# ATSAM4CMP32C_1 register map
Vendor: Atmel; Series: SAM4CM; File version: 0
CPU: CM4 r0p0, selectable endian, no MPU, FPU, 4 interrupt priority bits
Registers are 32-bit, read-write, reset 0x0 unless marked. A register's access mark holds for its fields unless they carry their own. Offsets are from the block's base; [hi:lo] are bit positions; {n}, {i} and the like mark numbered series; 'fields as' and 'values as' point back to an identical list.

## SLCDC — Segment LCD Controller
Base 0x4003C000; register names take the prefix SLCDC_
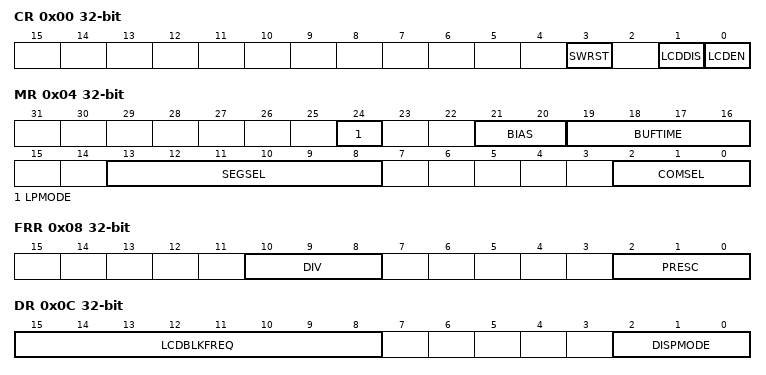
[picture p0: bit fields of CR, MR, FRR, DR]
0x00 CR wo reset not defined — SLCDC Control Register
  [3] SWRST — Software Reset
  [1] LCDDIS — Disable LCDC
  [0] LCDEN — Enable the LCDC
0x04 MR — SLCDC Mode Register
  [24] LPMODE — Low Power Mode (Taken into account from the next begin of frame.)
  [21:20] BIAS — LCD Display Configuration
    0=STATIC; 1=BIAS_1_2; 2=BIAS_1_3
  [19:16] BUFTIME — Buffer On-Time
    0=OFF (Nominal drive time is 0% of SCLK period); 1=X2_SCLK_PERIOD (Nominal drive time is 2 periods of SCLK clock); 2=X4_SCLK_PERIOD (Nominal drive time is 4 periods of SCLK clock); 3=X8_SCLK_PERIOD (Nominal drive time is 8 periods of SCLK clock); 4=X16_SCLK_PERIOD (Nominal drive time is 16 periods of SCLK clock); 5=X32_SCLK_PERIOD (Nominal drive time is 32 periods of SCLK clock); 6=X64_SCLK_PERIOD (Nominal drive time is 64 periods of SCLK clock); 7=X128_SCLK_PERIOD (Nominal drive time is 128 periods of SCLK clock); 8=PERCENT_50 (Nominal drive time is 50% of SCLK period); 9=PERCENT_100 (Nominal drive time is 100% of SCLK period)
  [13:8] SEGSEL — Selection of the Number of Segments
  [2:0] COMSEL — Selection of the Number of Commons
    0=COM_0 (COM0 is driven by SLCDC, COM1:5 are driven by digital function); 1=COM_0TO1 (COM0:1 are driven by SLCDC, COM2:5 are driven by digital function); 2=COM_0TO2 (COM0:2 are driven by SLCDC, COM3:5 are driven by digital function); 3=COM_0TO3 (COM0:3 are driven by SLCDC, COM4:5 are driven by digital function); 4=COM_0TO4 (COM0:4 are driven by SLCDC, COM5 is driven by digital function); 5=COM_0TO5 (COM0:5 are driven by SLCDC, No COM pin driven by digital function)
0x08 FRR — SLCDC Frame Rate Register
  [10:8] DIV — Clock Division
    {v}=PRESC_CLK_DIV{v+1} (clock output from prescaler is divided by {v+1}) (v=0..7)
  [2:0] PRESC — Clock Prescaler
    0=SCLK_DIV8 (slow clock is divided by 8); 1=SCLK_DIV16 (slow clock is divided by 16); 2=SCLK_DIV32 (slow clock is divided by 32); 3=SCLK_DIV64 (slow clock is divided by 64); 4=SCLK_DIV128 (slow clock is divided by 128); 5=SCLK_DIV256 (slow clock is divided by 256); 6=SCLK_DIV512 (slow clock is divided by 512); 7=SCLK_DIV1024 (slow clock is divided by 1024)
0x0C DR — SLCDC Display Register
  [15:8] LCDBLKFREQ — LCD Blinking Frequency Selection
  [2:0] DISPMODE — Display Mode Register
    0=NORMAL (Normal Mode: Latched data are displayed.); 1=FORCE_OFF (Force Off Mode: All pixels are invisible. (The SLCDC memory is unchanged.)); 2=FORCE_ON (Force On Mode All pixels are visible. (The SLCDC memory is unchanged.)); 3=BLINKING (Blinking Mode: All pixels are alternately turned off to the predefined state in SLCDC memory at LCDBLKFREQ frequency. (The SLCDC memory is unchanged.)); 4=INVERTED (Inverted Mode: All pixels are set in the inverted state as defined in SLCDC memory. (The SLCDC memory is unchanged.)); 5=INVERTED_BLINK (Inverted Blinking Mode: All pixels are alternately turned off to the predefined opposite state in SLCDC memory at LCDBLKFREQ frequency. (The SLCDC memory is unchanged.)); 6=USER_BUFFER_LOAD (User Buffer Only Load Mode: Blocks the automatic transfer from User Buffer to Display Buffer.); 7=BUFFERS_SWAP (Buffer Swap Mode: All pixels are alternatively assigned to the state defined in the User Buffer, then to the state defined in the Display Buffer at LCDBLKFREQ frequency.)
0x10 SR ro — SLCDC Status Register
  [0] ENA — Enable Status (Automatically Set/Reset)
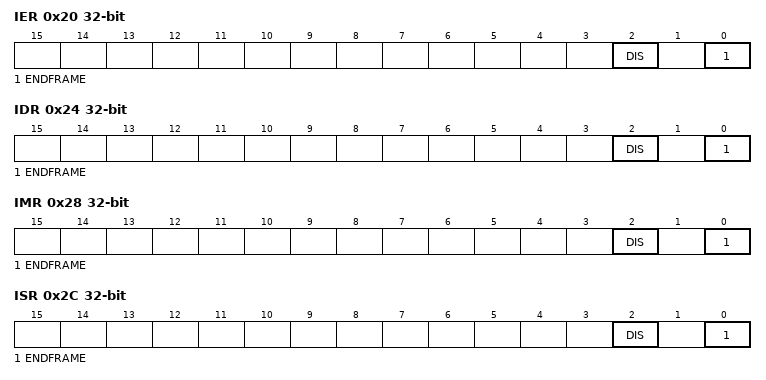
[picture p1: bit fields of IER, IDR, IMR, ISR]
0x20 IER wo reset not defined — SLCDC Interrupt Enable Register
  [2] DIS — Disable Interrupt Enable
  [0] ENDFRAME — End of Frame Interrupt Enable
0x24 IDR wo reset not defined — SLCDC Interrupt Disable Register
  [2] DIS — Disable Interrupt Disable
  [0] ENDFRAME — End of Frame Interrupt Disable
0x28 IMR wo reset not defined — SLCDC Interrupt Mask Register
  [2] DIS — Disable Interrupt Mask
  [0] ENDFRAME — End of Frame Interrupt Mask
0x2C ISR ro — SLCDC Interrupt Status Register
  fields as IMR
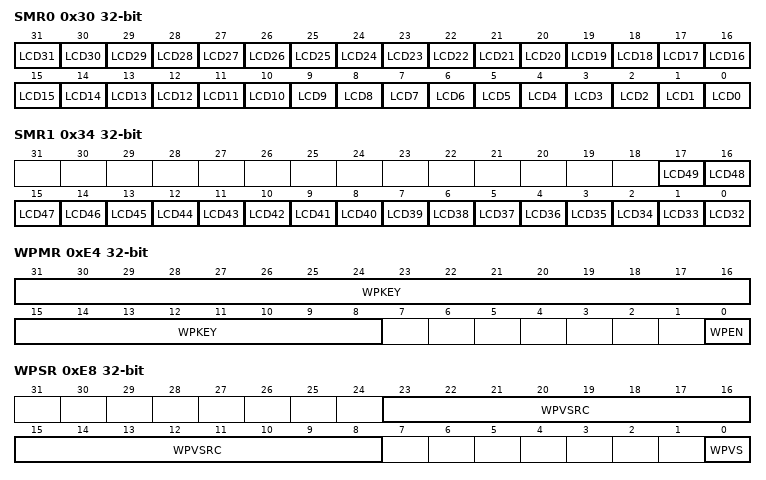
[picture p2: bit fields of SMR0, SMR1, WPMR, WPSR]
0x30 SMR0 — SLCDC Segment Map Register 0
  [n] LCD{n} (n=0..31) — LCD Segment Mapped on SEGx I/O pin
0x34 SMR1 — SLCDC Segment Map Register 1
  [n-32] LCD{n} (n=32..49) — LCD Segment Mapped on SEGx I/O pin
0xE4 WPMR — SLCDC Write Protect Mode Register
  [31:8] WPKEY — Write Protect KEY
  [0] WPEN — Write Protect Enable
0xE8 WPSR ro — SLCDC Write Protect Status Register
  [23:8] WPVSRC — Write Protect Violation Source
  [0] WPVS — Write Protect Violation Status
{0x200+8i} LMEMR{i} (i=0..5) — SLCDC LSB Memory Register (com = {i})
  [31:0] LPIXEL — LSB Pixels pattern associated to COMx terminal
{0x204+8i} MMEMR{i} (i=0..5) — SLCDC MSB Memory Register (com = {i})
  [31:0] MPIXEL — MSB Pixels pattern associated to COMx terminal

## Notices in the file
SAM Software Package License
Copyright (c) 2015, Atmel Corporation
All rights reserved.
Redistribution and use in source and binary forms, with or without
modification, are permitted provided that the following condition is met:
- Redistributions of source code must retain the above copyright notice,
this list of conditions and the disclaimer below.
Atmel's name may not be used to endorse or promote products derived from
this software without specific prior written permission.
DISCLAIMER:  THIS SOFTWARE IS PROVIDED BY ATMEL "AS IS" AND ANY EXPRESS OR
IMPLIED WARRANTIES, INCLUDING, BUT NOT LIMITED TO, THE IMPLIED WARRANTIES OF
MERCHANTABILITY, FITNESS FOR A PARTICULAR PURPOSE AND NON-INFRINGEMENT ARE
DISCLAIMED. IN NO EVENT SHALL ATMEL BE LIABLE FOR ANY DIRECT, INDIRECT,
INCIDENTAL, SPECIAL, EXEMPLARY, OR CONSEQUENTIAL DAMAGES (INCLUDING, BUT NOT
LIMITED TO, PROCUREMENT OF SUBSTITUTE GOODS OR SERVICES; LOSS OF USE, DATA,
OR PROFITS; OR BUSINESS INTERRUPTION) HOWEVER CAUSED AND ON ANY THEORY OF
LIABILITY, WHETHER IN CONTRACT, STRICT LIABILITY, OR TORT (INCLUDING
NEGLIGENCE OR OTHERWISE) ARISING IN ANY WAY OUT OF THE USE OF THIS SOFTWARE,
EVEN IF ADVISED OF THE POSSIBILITY OF SUCH DAMAGE.
